# CPSW_ALE register map
Vendor: Texas Instruments
Peripheral module from a debugger description file (folder am437x).
Registers are 32-bit, access per field, no defined reset value unless marked. A register's access mark holds for its fields unless they carry their own. Offsets are as the file gives them; lines under a group give offsets from that group; [hi:lo] are bit positions; {n}, {i} and the like mark numbered series; 'fields as' and 'values as' point back to an identical list; <NAME> marks a mode.

## CPSW_ALE
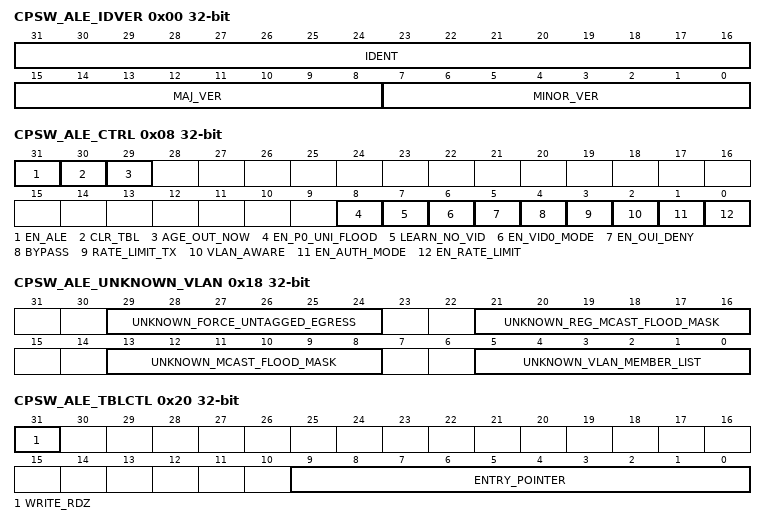
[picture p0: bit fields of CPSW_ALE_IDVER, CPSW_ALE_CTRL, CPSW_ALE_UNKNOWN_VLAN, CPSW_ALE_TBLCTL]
0x00 CPSW_ALE_IDVER ro — ADDRESS LOOKUP ENGINE ID/VERSION REGISTER
  [31:16] IDENT — ALE Identification Value
  [15:8] MAJ_VER — ALE Major Version Value
  [7:0] MINOR_VER — ALE Minor Version Value
0x08 CPSW_ALE_CTRL — ADDRESS LOOKUP ENGINE CONTROL REGISTER
  [31] EN_ALE rw — Enable ALE
    1=en_2_0x1 (Enable ALE packet processing); 0=en_1_0x0 (Drop all packets)
  [30] CLR_TBL rw — Clear ALE address table - Setting this bit causes the ALE hardware to write all table bit values to zero. [[br]]Software must perform a clear table operation as part of the ALE setup/configuration process. [[br]]Setting this bit causes all ALE accesses to be held up for 64 clocks while the clear is performed. [[br]]Access to all ALE registers will be blocked (wait states) until the 64 clocks have completed. [[br]]This bit cannot be read as one because the read is blocked until the clear table is completed at which time this bit is cleared to zero. [[br]]
  [29] AGE_OUT_NOW rw — Age Out Address Table Now - Setting this bit causes the ALE hardware to remove (free up) any ageable table entry that does not have a set touch bit. [[br]]This bit is cleared when the age out process has completed. [[br]]This bit may be read. [[br]]The age out process takes 4096 clocks best case (no ale packet processing during ageout) and 66550 clocks absolute worst case. [[br]]
  [8] EN_P0_UNI_FLOOD rw — Enable Port 0 (Host Port) unicast flood
    1=en_2_0x1 (Flood unknown unicast packets to host port (p0)); 0=en_1_0x0 (Do not flood unknown unicast packets to host port (p0))
  [7] LEARN_NO_VID rw
    1=en_2_0x1 (VID is not learned with the source address (source address is not tied to VID).); 0=en_1_0x0 (VID is learned with the source address)
  [6] EN_VID0_MODE rw — Enable VLAN ID = 0 Mode
    1=en_2_0x1 (Process the packet with VID = 0.); 0=en_1_0x0 (Process the packet with VID = PORT_VLAN[11 to 0])
  [5] EN_OUI_DENY rw — Enable OUI Deny Mode - When set this bit indicates that a packet with a non OUI table entry matching source address will be dropped to the host unless the destination address matches a multicast table entry with the super bit set. [[br]]
  [4] BYPASS rw — ALE Bypass - When set, all packets received on ports 0 and 1 are sent to the host (only to the host).
  [3] RATE_LIMIT_TX rw — Rate Limit Transmit mode
    1=en_2_0x1 (Broadcast and multicast rate limit counters are transmit port based); 0=en_1_0x0 (Broadcast and multicast rate limit counters are received port based)
  [2] VLAN_AWARE rw — ALE VLAN Aware - Determines what is done if VLAN not found. [[br]]
    1=en_2_0x1 (Drop packet if VLAN not found); 0=en_1_0x0 (Flood if VLAN not found)
  [1] EN_AUTH_MODE rw — Enable MAC Authorization Mode - Mac authorization mode requires that all table entries be made by the host software. [[br]]There are no learned address in authorization mode and the packet will be dropped if the source address is not found (and the destination address is not a multicast address with the super table entry bit set).
    1=en_2_0x1 (The ALE is in MAC authorization mode.); 0=en_1_0x0 (The ALE is not in MAC authorization mode.)
  [0] EN_RATE_LIMIT rw — Enable Broadcast and Multicast Rate Limit
    1=en_2_0x1 (Broadcast/Multicast packet reception limited to the port control register rate limit fields); 0=en_1_0x0 (Broadcast/Multicast rates not limited)
0x10 CPSW_ALE_PRESCALE — ADDRESS LOOKUP ENGINE PRESCALE REGISTER
  [19:0] PRESCALE rw — ALE Prescale Register - The input clock is divided by this value for use in the multicast/broadcast rate limiters. [[br]]The minimum operating value is 0x10. [[br]]The prescaler is off when the value is zero. [[br]]
0x18 CPSW_ALE_UNKNOWN_VLAN — ADDRESS LOOKUP ENGINE UNKNOWN VLAN REGISTER
  [29:24] UNKNOWN_FORCE_UNTAGGED_EGRESS rw — Unknown VLAN Force Untagged Egress.
  [21:16] UNKNOWN_REG_MCAST_FLOOD_MASK rw — Unknown VLAN Registered Multicast Flood Mask
  [13:8] UNKNOWN_MCAST_FLOOD_MASK rw — Unknown VLAN Multicast Flood Mask
  [5:0] UNKNOWN_VLAN_MEMBER_LIST rw
0x20 CPSW_ALE_TBLCTL — ADDRESS LOOKUP ENGINE TABLE CONTROL
  [31] WRITE_RDZ rw — Write Bit - This bit is always read as zero. [[br]]Writing a 1 to this bit causes the three table word register values to be written to the entry_pointer location in the address table. [[br]]Writing a 0 to this bit causes the three table word register values to be loaded from the entry_pointer location in the address table so that they may be subsequently read. [[br]]A read of any ALE address location will be stalled until the read or write has completed. [[br]]
  [9:0] ENTRY_POINTER rw — Table Entry Pointer - The entry_pointer contains the table entry value that will be read/written with accesses to the table word registers. [[br]]
0x34 CPSW_ALE_TBLW2 — ADDRESS LOOKUP ENGINE TABLE WORD 2 REGISTER
  [7:0] ENTRY71_64 rw — Table entry bits [[br]]71:64
0x38 CPSW_ALE_TBLW1 rw — ADDRESS LOOKUP ENGINE TABLE WORD 1 REGISTER
  [31:0] ENTRY63_32 — Table entry bits 63:32
0x3C CPSW_ALE_TBLW0 rw — ADDRESS LOOKUP ENGINE TABLE WORD 0 REGISTER
  [31:0] ENTRY31_0 — Table entry bits 31:0
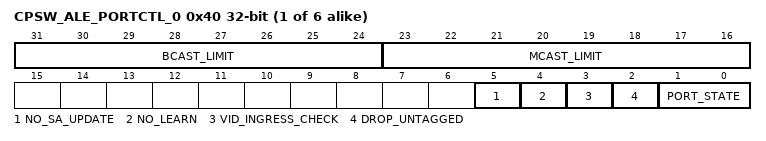
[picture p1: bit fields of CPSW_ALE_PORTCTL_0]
{0x40+4i} CPSW_ALE_PORTCTL_{i} (i=0..5) — ADDRESS LOOKUP ENGINE PORT x CONTROL REGISTER
  [31:24] BCAST_LIMIT rw — Broadcast Packet Rate Limit - Each prescale pulse loads this field into the port broadcast rate limit counter. [[br]]The port counters are decremented with each packet received or transmitted depending on whether the mode is transmit or receive. [[br]]If the counters decrement to zero, then further packets are rate limited until the next prescale pulse. [[br]]Broadcast rate limiting is enabled by a non-zero value in this field
  [23:16] MCAST_LIMIT rw — Multicast Packet Rate Limit - Each prescale pulse loads this field into the port multicast rate limit counter. [[br]]The port counters are decremented with each packet received or transmitted depending on whether the mode is transmit or receive. [[br]]If the counters decrement to zero, then further packets are rate limited until the next prescale pulse. [[br]]Multicast rate limiting is enabled by a non-zero value in this field. [[br]]
  [5] NO_SA_UPDATE rw — No Souce Address Update - When set the port is disabled from updating the source port number in an ALE table entry. [[br]]
  [4] NO_LEARN rw — No Learn Mode - When set the port is disabled from learning an address.
  [3] VID_INGRESS_CHECK rw — VLAN ID Ingress Check - If VLAN not found then drop the packet. [[br]]Packets with an unknown (default) VLAN will be dropped. [[br]]
  [2] DROP_UNTAGGED rw — Drop Untagged Packets - Drop non-VLAN tagged ingress packets.
  [1:0] PORT_STATE rw
    3=en_4_0x3 (Forward); 2=en_3_0x2 (Learn); 1=en_2_0x1 (Blocked); 0=en_1_0x0 (Disabled)
